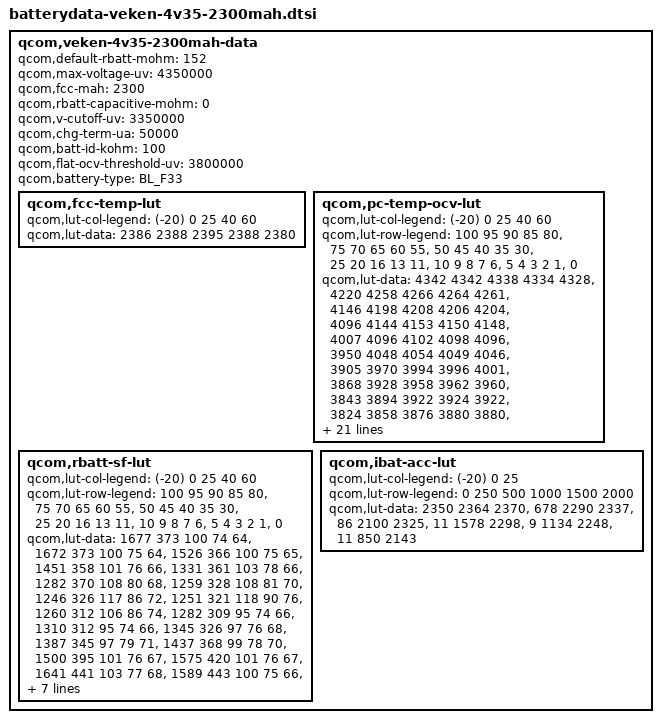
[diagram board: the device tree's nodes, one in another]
/* Copyright (c) 2014, The Linux Foundation. All rights reserved.
 *
 * This program is free software; you can redistribute it and/or modify
 * it under the terms of the GNU General Public License version 2 and
 * only version 2 as published by the Free Software Foundation.
 *
 * This program is distributed in the hope that it will be useful,
 * but WITHOUT ANY WARRANTY; without even the implied warranty of
 * MERCHANTABILITY or FITNESS FOR A PARTICULAR PURPOSE.  See the
 * GNU General Public License for more details.
 */

qcom,veken-4v35-2300mah-data {
	qcom,default-rbatt-mohm = <152>;
	qcom,max-voltage-uv = <4350000>;
	qcom,fcc-mah = <2300>;
	qcom,rbatt-capacitive-mohm = <0>;
	qcom,v-cutoff-uv = <3350000>;
	qcom,chg-term-ua = <50000>;
	qcom,batt-id-kohm = <100>;
	qcom,flat-ocv-threshold-uv = <3800000>;
	qcom,battery-type = "BL_F33";

	qcom,fcc-temp-lut {
		qcom,lut-col-legend = <(-20) 0 25 40 60>;
		qcom,lut-data = <2386 2388 2395 2388 2380>;
	};

	qcom,pc-temp-ocv-lut {
		qcom,lut-col-legend = <(-20) 0 25 40 60>;
		qcom,lut-row-legend = <100 95 90 85 80>,
				<75 70 65 60 55>,
				<50 45 40 35 30>,
				<25 20 16 13 11>,
				<10 9 8 7 6>,
				<5 4 3 2 1>,
				<0>;
		qcom,lut-data = <4342 4342 4338 4334 4328>,
				<4220 4258 4266 4264 4261>,
				<4146 4198 4208 4206 4204>,
				<4096 4144 4153 4150 4148>,
				<4007 4096 4102 4098 4096>,
				<3950 4048 4054 4049 4046>,
				<3905 3970 3994 3996 4001>,
				<3868 3928 3958 3962 3960>,
				<3843 3894 3922 3924 3922>,
				<3824 3858 3876 3880 3880>,
				<3806 3828 3840 3840 3840>,
				<3790 3806 3816 3816 3816>,
				<3776 3791 3798 3798 3797>,
				<3760 3779 3782 3783 3782>,
				<3745 3768 3771 3768 3763>,
				<3728 3754 3759 3752 3740>,
				<3710 3733 3742 3734 3720>,
				<3690 3713 3718 3712 3698>,
				<3673 3701 3694 3687 3674>,
				<3658 3694 3688 3681 3670>,
				<3648 3690 3686 3680 3669>,
				<3636 3687 3684 3679 3668>,
				<3622 3683 3683 3677 3666>,
				<3606 3678 3680 3674 3664>,
				<3586 3666 3674 3668 3655>,
				<3560 3644 3652 3646 3630>,
				<3526 3604 3608 3604 3584>,
				<3478 3543 3546 3544 3524>,
				<3406 3453 3463 3461 3440>,
				<3284 3303 3323 3336 3308>,
				<3000 3000 3000 3000 3000>;
	};

	qcom,rbatt-sf-lut {
		qcom,lut-col-legend = <(-20) 0 25 40 60>;
		qcom,lut-row-legend = <100 95 90 85 80>,
				<75 70 65 60 55>,
				<50 45 40 35 30>,
				<25 20 16 13 11>,
				<10 9 8 7 6>,
				<5 4 3 2 1>,
				<0>;
		qcom,lut-data = <1677 373 100 74 64>,
				<1672 373 100 75 64>,
				<1526 366 100 75 65>,
				<1451 358 101 76 66>,
				<1331 361 103 78 66>,
				<1282 370 108 80 68>,
				<1259 328 108 81 70>,
				<1246 326 117 86 72>,
				<1251 321 118 90 76>,
				<1260 312 106 86 74>,
				<1282 309 95 74 66>,
				<1310 312 95 74 66>,
				<1345 326 97 76 68>,
				<1387 345 97 79 71>,
				<1437 368 99 78 70>,
				<1500 395 101 76 67>,
				<1575 420 101 76 67>,
				<1641 441 103 77 68>,
				<1589 443 100 75 66>,
				<1662 468 100 76 67>,
				<1734 484 102 76 68>,
				<1835 507 104 78 70>,
				<2001 532 109 80 72>,
				<2230 561 112 83 74>,
				<2507 588 118 85 74>,
				<2883 614 116 83 70>,
				<3451 653 116 82 71>,
				<4336 718 122 85 74>,
				<6114 821 136 92 82>,
				<12229 1261 272 120 113>,
				<134648 98748 30618 31201 17362>;
	};
                qcom,ibat-acc-lut {
		qcom,lut-col-legend = <(-20) 0 25>;
		qcom,lut-row-legend = <0 250 500 1000 1500 2000>;
		qcom,lut-data = <2350 2364 2370>,
		<678 2290 2337>,
		<86 2100 2325>,
		<11 1578 2298>,
		<9 1134 2248>,
		<11 850 2143>;
    };
};
